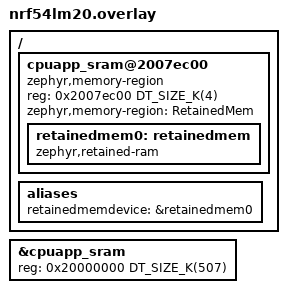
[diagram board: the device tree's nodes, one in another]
/*
 * Copyright (c) 2026 Nordic Semiconductor ASA
 *
 * SPDX-License-Identifier: LicenseRef-Nordic-5-Clause
 */

/* 4 KB retained RAM, same layout as zephyr/samples/boards/nordic/system_off.
 * Not part of the default build, so that cpuapp gets all the RAM. Added by the retram snippet
 * (snippets/retram) together with CONFIG_APP_USE_RETAINED_MEM=y.
 */
/ {
	cpuapp_sram@2007ec00 {
		compatible = "zephyr,memory-region", "mmio-sram";
		reg = <0x2007ec00 DT_SIZE_K(4)>;
		zephyr,memory-region = "RetainedMem";
		status = "okay";

		retainedmem0: retainedmem {
			compatible = "zephyr,retained-ram";
			status = "okay";
		};
	};

	aliases {
		retainedmemdevice = &retainedmem0;
	};
};

&cpuapp_sram {
	/* Shrink SRAM size to avoid overlap with retained memory region:
	 * 511 - 4 = 507KB = 0x7ec00
	 */
	reg = <0x20000000 DT_SIZE_K(507)>;
	ranges = <0x0 0x20000000 0x7ec00>;
};
